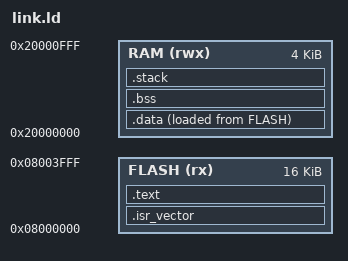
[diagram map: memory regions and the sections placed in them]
/* Cortex-M style layout: code and constants in FLASH, data copied to RAM at boot. */
ENTRY(reset_handler)

MEMORY
{
    FLASH (rx)  : ORIGIN = 0x08000000, LENGTH = 16K
    RAM   (rwx) : ORIGIN = 0x20000000, LENGTH = 4K
}

_stack_size = 0x400;

SECTIONS
{
    .isr_vector :
    {
        . = ALIGN(4);
        KEEP(*(.isr_vector))
        . = ALIGN(4);
    } > FLASH

    .text :
    {
        . = ALIGN(4);
        *(.text*)
        *(.rodata*)
        . = ALIGN(4);
        _etext = .;
    } > FLASH

    _sidata = LOADADDR(.data);

    .data :
    {
        . = ALIGN(4);
        _sdata = .;
        *(.data*)
        . = ALIGN(4);
        _edata = .;
    } > RAM AT> FLASH

    .bss (NOLOAD) :
    {
        . = ALIGN(4);
        _sbss = .;
        *(.bss*)
        *(COMMON)
        . = ALIGN(4);
        _ebss = .;
    } > RAM

    .stack (NOLOAD) :
    {
        . = ALIGN(8);
        . = . + _stack_size;
        PROVIDE(_estack = .);
    } > RAM

    /DISCARD/ :
    {
        *(.ARM.exidx*)
        *(.comment)
    }
}
